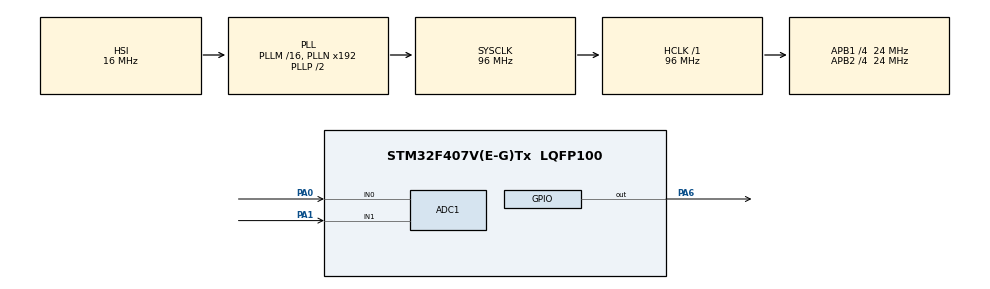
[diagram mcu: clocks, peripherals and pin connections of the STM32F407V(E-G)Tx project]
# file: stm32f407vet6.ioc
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ADC1.Channel-0\#ChannelRegularConversion=ADC_CHANNEL_0
ADC1.Channel-1\#ChannelRegularConversion=ADC_CHANNEL_1
ADC1.ClockPrescaler=ADC_CLOCK_SYNC_PCLK_DIV2
ADC1.ContinuousConvMode=DISABLE
ADC1.DiscontinuousConvMode=ENABLE
ADC1.EOCSelection=ADC_EOC_SINGLE_CONV
ADC1.NbrOfConversion=2
ADC1.NbrOfConversionFlag=1
ADC1.Rank-0\#ChannelRegularConversion=1
ADC1.Rank-1\#ChannelRegularConversion=2
ADC1.SamplingTime-0\#ChannelRegularConversion=ADC_SAMPLETIME_28CYCLES
ADC1.SamplingTime-1\#ChannelRegularConversion=ADC_SAMPLETIME_28CYCLES
ADC1.master=1
Mcu.Family=STM32F4
Mcu.Name=STM32F407V(E-G)Tx
Mcu.Package=LQFP100
NVIC.PriorityGroup=NVIC_PRIORITYGROUP_4
PA0-WKUP.Signal=ADCx_IN0
PA1.Signal=ADCx_IN1
PA13.Mode=Trace_Asynchronous_SW
PA13.Signal=SYS_JTMS-SWDIO
PA14.Mode=Trace_Asynchronous_SW
PA14.Signal=SYS_JTCK-SWCLK
PA6.Signal=GPIO_Output
PB3.Mode=Trace_Asynchronous_SW
PB3.Signal=SYS_JTDO-SWO
ProjectManager.HeapSize=0x200
ProjectManager.StackSize=0x400
ProjectManager.TargetToolchain=STM32CubeIDE
RCC.AHBFreq_Value=96000000
RCC.APB1CLKDivider=RCC_HCLK_DIV4
RCC.APB1Freq_Value=24000000
RCC.APB1TimFreq_Value=48000000
RCC.APB2CLKDivider=RCC_HCLK_DIV4
RCC.APB2Freq_Value=24000000
RCC.APB2TimFreq_Value=48000000
RCC.CortexFreq_Value=96000000
RCC.HCLKFreq_Value=96000000
RCC.HSE_VALUE=25000000
RCC.HSI_VALUE=16000000
RCC.LSE_VALUE=32768
RCC.SYSCLKFreq_VALUE=96000000
RCC.SYSCLKSource=RCC_SYSCLKSOURCE_PLLCLK
RCC.VCOOutputFreq_Value=192000000
SH.ADCx_IN0.0=ADC1_IN0,IN0
SH.ADCx_IN0.1=ADC3_IN0
SH.ADCx_IN1.0=ADC1_IN1,IN1
board=custom

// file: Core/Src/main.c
/* USER CODE BEGIN Header */
/**
  ******************************************************************************
  * @file           : main.c
  * @brief          : Main program body
  ******************************************************************************
  * @attention
  *
  * Copyright (c) 2025 STMicroelectronics.
  * All rights reserved.
  *
  * This software is licensed under terms that can be found in the LICENSE file
  * in the root directory of this software component.
  * If no LICENSE file comes with this software, it is provided AS-IS.
  *
  ******************************************************************************
  */
/* USER CODE END Header */
#include "main.h"

/* USER CODE BEGIN Includes */
#include <stdio.h>
/* USER CODE END Includes */

/* USER CODE BEGIN PM */
#define K1 GPIO_PIN_3
#define K0 GPIO_PIN_4

#define D2 GPIO_PIN_6
#define D3 GPIO_PIN_7
/* USER CODE END PM */

ADC_HandleTypeDef hadc1;

/* USER CODE BEGIN PV */
int blink_count = 0;
/* USER CODE END PV */

void SystemClock_Config(void);
static void MX_GPIO_Init(void);
static void MX_ADC1_Init(void);

/* USER CODE BEGIN 0 */
int adc_ch0_val = 0;
int adc_ch1_val = 0;
int x = 0;
/* USER CODE END 0 */

int main(void)
{

  /* MCU Configuration--------------------------------------------------------*/

  /* Reset of all peripherals, Initializes the Flash interface and the Systick. */
  HAL_Init();

  /* Configure the system clock */
  SystemClock_Config();

  /* Initialize all configured peripherals */
  MX_GPIO_Init();
  MX_ADC1_Init();

  /* Infinite loop */
  /* USER CODE BEGIN WHILE */
  while (1)
  {
	  HAL_GPIO_TogglePin(GPIOA, GPIO_PIN_6);
      HAL_Delay(1);
      blink_count = ++blink_count%500;
    /* USER CODE END WHILE */

  }
}

void SystemClock_Config(void)
{
  RCC_OscInitTypeDef RCC_OscInitStruct = {0};
  RCC_ClkInitTypeDef RCC_ClkInitStruct = {0};

  /** Configure the main internal regulator output voltage
  */
  __HAL_RCC_PWR_CLK_ENABLE();
  __HAL_PWR_VOLTAGESCALING_CONFIG(PWR_REGULATOR_VOLTAGE_SCALE1);

  /** Initializes the RCC Oscillators according to the specified parameters
  * in the RCC_OscInitTypeDef structure.
  */
  RCC_OscInitStruct.OscillatorType = RCC_OSCILLATORTYPE_HSI;
  RCC_OscInitStruct.HSIState = RCC_HSI_ON;
  RCC_OscInitStruct.HSICalibrationValue = RCC_HSICALIBRATION_DEFAULT;
  RCC_OscInitStruct.PLL.PLLState = RCC_PLL_ON;
  RCC_OscInitStruct.PLL.PLLSource = RCC_PLLSOURCE_HSI;
  RCC_OscInitStruct.PLL.PLLM = 16;
  RCC_OscInitStruct.PLL.PLLN = 192;
  RCC_OscInitStruct.PLL.PLLP = RCC_PLLP_DIV2;
  RCC_OscInitStruct.PLL.PLLQ = 4;
  if (HAL_RCC_OscConfig(&RCC_OscInitStruct) != HAL_OK)
  {
    Error_Handler();
  }

  /** Initializes the CPU, AHB and APB buses clocks
  */
  RCC_ClkInitStruct.ClockType = RCC_CLOCKTYPE_HCLK|RCC_CLOCKTYPE_SYSCLK
                              |RCC_CLOCKTYPE_PCLK1|RCC_CLOCKTYPE_PCLK2;
  RCC_ClkInitStruct.SYSCLKSource = RCC_SYSCLKSOURCE_PLLCLK;
  RCC_ClkInitStruct.AHBCLKDivider = RCC_SYSCLK_DIV1;
  RCC_ClkInitStruct.APB1CLKDivider = RCC_HCLK_DIV4;
  RCC_ClkInitStruct.APB2CLKDivider = RCC_HCLK_DIV4;

  if (HAL_RCC_ClockConfig(&RCC_ClkInitStruct, FLASH_LATENCY_3) != HAL_OK)
  {
    Error_Handler();
  }
}

static void MX_ADC1_Init(void)
{

  ADC_ChannelConfTypeDef sConfig = {0};

  /** Configure the global features of the ADC (Clock, Resolution, Data Alignment and number of conversion)
  */
  hadc1.Instance = ADC1;
  hadc1.Init.ClockPrescaler = ADC_CLOCK_SYNC_PCLK_DIV2;
  hadc1.Init.Resolution = ADC_RESOLUTION_12B;
  hadc1.Init.ScanConvMode = ENABLE;
  hadc1.Init.ContinuousConvMode = DISABLE;
  hadc1.Init.DiscontinuousConvMode = ENABLE;
  hadc1.Init.NbrOfDiscConversion = 1;
  hadc1.Init.ExternalTrigConvEdge = ADC_EXTERNALTRIGCONVEDGE_NONE;
  hadc1.Init.ExternalTrigConv = ADC_SOFTWARE_START;
  hadc1.Init.DataAlign = ADC_DATAALIGN_RIGHT;
  hadc1.Init.NbrOfConversion = 2;
  hadc1.Init.DMAContinuousRequests = DISABLE;
  hadc1.Init.EOCSelection = ADC_EOC_SINGLE_CONV;
  if (HAL_ADC_Init(&hadc1) != HAL_OK)
  {
    Error_Handler();
  }

  /** Configure for the selected ADC regular channel its corresponding rank in the sequencer and its sample time.
  */
  sConfig.Channel = ADC_CHANNEL_0;
  sConfig.Rank = 1;
  sConfig.SamplingTime = ADC_SAMPLETIME_28CYCLES;
  if (HAL_ADC_ConfigChannel(&hadc1, &sConfig) != HAL_OK)
  {
    Error_Handler();
  }

  /** Configure for the selected ADC regular channel its corresponding rank in the sequencer and its sample time.
  */
  sConfig.Channel = ADC_CHANNEL_1;
  sConfig.Rank = 2;
  if (HAL_ADC_ConfigChannel(&hadc1, &sConfig) != HAL_OK)
  {
    Error_Handler();
  }

}

static void MX_GPIO_Init(void)
{
  GPIO_InitTypeDef GPIO_InitStruct = {0};

  /* GPIO Ports Clock Enable */
  __HAL_RCC_GPIOA_CLK_ENABLE();
  __HAL_RCC_GPIOB_CLK_ENABLE();

  /*Configure GPIO pin Output Level */
  HAL_GPIO_WritePin(GPIOA, GPIO_PIN_6, GPIO_PIN_RESET);

  /*Configure GPIO pin : PA0 */
  GPIO_InitStruct.Pin = GPIO_PIN_0;
  GPIO_InitStruct.Mode = GPIO_MODE_ANALOG;
  GPIO_InitStruct.Pull = GPIO_NOPULL;
  HAL_GPIO_Init(GPIOA, &GPIO_InitStruct);

  /*Configure GPIO pin : PA6 */
  GPIO_InitStruct.Pin = GPIO_PIN_6;
  GPIO_InitStruct.Mode = GPIO_MODE_OUTPUT_PP;
  GPIO_InitStruct.Pull = GPIO_NOPULL;
  GPIO_InitStruct.Speed = GPIO_SPEED_FREQ_LOW;
  HAL_GPIO_Init(GPIOA, &GPIO_InitStruct);

}

/* USER CODE BEGIN 4 */
int _write(int file, char *ptr, int len)
{
  /* Implement your write code here, this is used by puts and printf for example */
  int i=0;
  for(i=0 ; i<len ; i++)
    ITM_SendChar((*ptr++));
  return len;
}
/* USER CODE END 4 */

void Error_Handler(void)
{
  __disable_irq();
  while (1)
  {
  }
}
